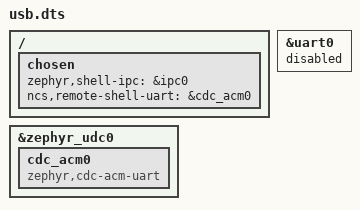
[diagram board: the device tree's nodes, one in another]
/*
 * Copyright (c) 2024 Nordic Semiconductor ASA
 *
 * SPDX-License-Identifier: LicenseRef-Nordic-5-Clause
 */

/ {
	chosen {
		zephyr,shell-ipc = &ipc0;
		ncs,remote-shell-uart = &cdc_acm0;
	};
};

&zephyr_udc0 {
	cdc_acm0: cdc_acm0 {
		compatible = "zephyr,cdc-acm-uart";
	};
};

&uart0 {
	status = "disabled";
};
